AUTOSAR XML (schema 3.1.2)
package /Components/SWC_InThMdlT
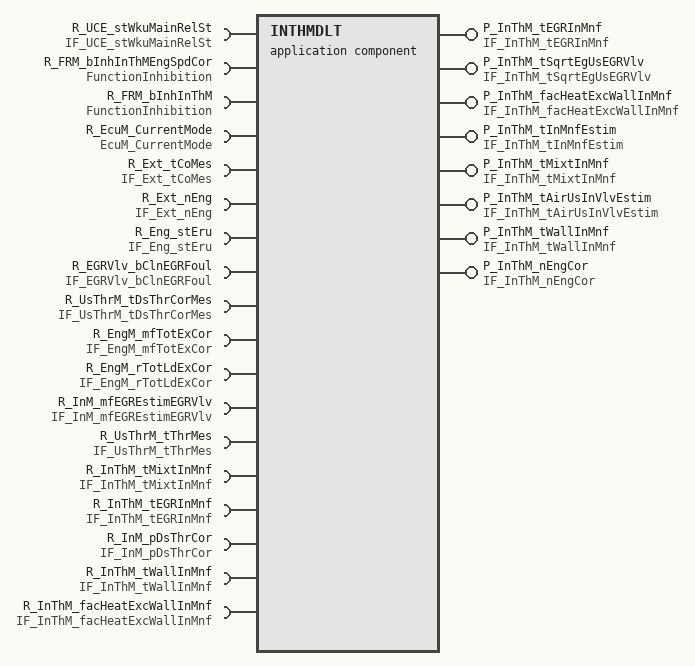
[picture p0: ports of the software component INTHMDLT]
  application software component type INTHMDLT  # InThMdlT
    require port R_UCE_stWkuMainRelSt: required-interface=IF_UCE_stWkuMainRelSt
    require port R_FRM_bInhInThMEngSpdCor: required-interface=FunctionInhibition
    require port R_FRM_bInhInThM: required-interface=FunctionInhibition
    8 x provide port:
      P_InThM_tEGRInMnf: unqueued-sender-com-spec{data-element=InThM_tEGRInMnf, can-invalidate=false, init-value=ConstantValue}, provided-interface=IF_InThM_tEGRInMnf
      P_InThM_tSqrtEgUsEGRVlv: unqueued-sender-com-spec{data-element=InThM_tSqrtEgUsEGRVlv, can-invalidate=false, init-value=ConstantValue1}, provided-interface=IF_InThM_tSqrtEgUsEGRVlv
      P_InThM_facHeatExcWallInMnf: unqueued-sender-com-spec{data-element=InThM_facHeatExcWallInMnf, can-invalidate=false, init-value=ConstantValue3}, provided-interface=IF_InThM_facHeatExcWallInMnf
      P_InThM_tInMnfEstim: unqueued-sender-com-spec{data-element=InThM_tInMnfEstim, can-invalidate=false, init-value=ConstantValue5}, provided-interface=IF_InThM_tInMnfEstim
      P_InThM_tMixtInMnf: unqueued-sender-com-spec{data-element=InThM_tMixtInMnf, can-invalidate=false, init-value=ConstantValue7}, provided-interface=IF_InThM_tMixtInMnf
      P_InThM_tAirUsInVlvEstim: unqueued-sender-com-spec{data-element=InThM_tAirUsInVlvEstim, can-invalidate=false, init-value=ConstantValue9}, provided-interface=IF_InThM_tAirUsInVlvEstim
      P_InThM_tWallInMnf: unqueued-sender-com-spec{data-element=InThM_tWallInMnf, can-invalidate=false, init-value=ConstantValue11}, provided-interface=IF_InThM_tWallInMnf
      P_InThM_nEngCor: unqueued-sender-com-spec{data-element=InThM_nEngCor, can-invalidate=false, init-value=ConstantValue13}, provided-interface=IF_InThM_nEngCor
    15 x require port:
      R_EcuM_CurrentMode: required-interface=EcuM_CurrentMode
      R_Ext_tCoMes: unqueued-receiver-com-spec{data-element=Ext_tCoMes, init-value=ConstantValue15, resync-time=0}, required-interface=IF_Ext_tCoMes
      R_Ext_nEng: unqueued-receiver-com-spec{data-element=Ext_nEng, init-value=ConstantValue17, resync-time=0}, required-interface=IF_Ext_nEng
      R_Eng_stEru: unqueued-receiver-com-spec{data-element=Eng_stEru, init-value=ConstantValue19, resync-time=0}, required-interface=IF_Eng_stEru
      R_EGRVlv_bClnEGRFoul: unqueued-receiver-com-spec{data-element=EGRVlv_bClnEGRFoul, init-value=ConstantValue21, resync-time=0}, required-interface=IF_EGRVlv_bClnEGRFoul
      R_UsThrM_tDsThrCorMes: unqueued-receiver-com-spec{data-element=UsThrM_tDsThrCorMes, init-value=UInt16InitValue, resync-time=0}, required-interface=IF_UsThrM_tDsThrCorMes
      R_EngM_mfTotExCor: unqueued-receiver-com-spec{data-element=EngM_mfTotExCor, init-value=ConstantValue23, resync-time=0}, required-interface=IF_EngM_mfTotExCor
      R_EngM_rTotLdExCor: unqueued-receiver-com-spec{data-element=EngM_rTotLdExCor, init-value=ConstantValue25, resync-time=0}, required-interface=IF_EngM_rTotLdExCor
      R_InM_mfEGREstimEGRVlv: unqueued-receiver-com-spec{data-element=InM_mfEGREstimEGRVlv, init-value=ConstantValue27, resync-time=0}, required-interface=IF_InM_mfEGREstimEGRVlv
      R_UsThrM_tThrMes: unqueued-receiver-com-spec{data-element=UsThrM_tThrMes, init-value=ConstantValue29, resync-time=0}, required-interface=IF_UsThrM_tThrMes
      R_InThM_tMixtInMnf: unqueued-receiver-com-spec{data-element=InThM_tMixtInMnf, init-value=ConstantValue31, resync-time=0}, required-interface=IF_InThM_tMixtInMnf
      R_InThM_tEGRInMnf: unqueued-receiver-com-spec{data-element=InThM_tEGRInMnf, init-value=ConstantValue, resync-time=0}, required-interface=IF_InThM_tEGRInMnf
      R_InM_pDsThrCor: unqueued-receiver-com-spec{data-element=InM_pDsThrCor, init-value=ConstantValue33, resync-time=0}, required-interface=IF_InM_pDsThrCor
      R_InThM_tWallInMnf: unqueued-receiver-com-spec{data-element=InThM_tWallInMnf, init-value=ConstantValue35, resync-time=0}, required-interface=IF_InThM_tWallInMnf
      R_InThM_facHeatExcWallInMnf: unqueued-receiver-com-spec{data-element=InThM_facHeatExcWallInMnf, init-value=ConstantValue37, resync-time=0}, required-interface=IF_InThM_facHeatExcWallInMnf
  23 x constant specification:
    ConstantValue
      value:
        integer literal ConstantValue: type=DT_InThM_tEGRInMnf, value=0
    ConstantValue1
      value:
        integer literal ConstantValue1: type=DT_InThM_tSqrtEgUsEGRVlv, value=0
    ConstantValue11
      value:
        integer literal ConstantValue11: type=DT_InThM_tWallInMnf, value=0
    ConstantValue13
      value:
        integer literal ConstantValue13: type=DT_InThM_nEngCor, value=0
    ConstantValue15
      value:
        integer literal ConstantValue15: type=DT_Ext_tCoMes, value=20
    ConstantValue17
      value:
        integer literal ConstantValue17: type=DT_Ext_nEng, value=0
    ConstantValue19
      value:
        integer literal ConstantValue19: type=DT_Eng_stEru, value=1
    ConstantValue21
      value:
        boolean literal ConstantValue21: type=DT_EGRVlv_bClnEGRFoul, value=false
    ConstantValue23
      value:
        integer literal ConstantValue23: type=DT_EngM_mfTotExCor, value=0
    ConstantValue25
      value:
        integer literal ConstantValue25: type=DT_EngM_rTotLdExCor, value=0
    ConstantValue27
      value:
        integer literal ConstantValue27: type=DT_InM_mfEGREstimEGRVlv, value=0
    ConstantValue29
      value:
        integer literal ConstantValue29: type=DT_UsThrM_tThrMes, value=0
    ConstantValue3
      value:
        integer literal ConstantValue3: type=DT_InThM_facHeatExcWallInMnf, value=0
    ConstantValue31
      value:
        integer literal ConstantValue31: type=DT_InThM_tMixtInMnf, value=0
    ConstantValue33
      value:
        integer literal ConstantValue33: type=DT_InM_pDsThrCor, value=0
    ConstantValue35
      value:
        integer literal ConstantValue35: type=DT_InThM_tWallInMnf, value=0
    ConstantValue37
      value:
        integer literal ConstantValue37: type=DT_InThM_facHeatExcWallInMnf, value=0
    ConstantValue5
      value:
        integer literal ConstantValue5: type=DT_InThM_tInMnfEstim, value=0
    ConstantValue7
      value:
        integer literal ConstantValue7: type=DT_InThM_tMixtInMnf, value=0
    ConstantValue9
      value:
        integer literal ConstantValue9: type=DT_InThM_tAirUsInVlvEstim, value=0
    InitValue_UInt16_0
      value:
        integer literal InitValue_UInt16_0: type=DT_InThM_tWallInCylHead_irv, value=0
    InitValue_UInt16_039
      value:
        integer literal InitValue_UInt16_039: type=DT_InThM_tEGRUsEGRVlv_irv, value=0
    UInt16InitValue
      value:
        integer literal UInt16InitValue: type=DT_UsThrM_tDsThrCorMes, value=0
  internal behavior IB_InThMdlT: component=INTHMDLT
    mode switch event EV_InThMdlT_001_MSE: start-on-event=RE_InThMdlT_001_MSE, activation=ENTRY, mode=R_EcuM_CurrentMode.currentMode.RUN
    6 x timing event, all with mode-dependency=dependent-on-mode=[R_UCE_stWkuMainRelSt.RCD_stWkuMainRelSt.PreMainWakeUp, R_UCE_stWkuMainRelSt.RCD_stWkuMainRelSt.PostMainWakeUp, R_UCE_stWkuMainRelSt.RCD_stWkuMainRelSt.Invalid]:
      EV_InThMdlT_006_TEV: start-on-event=RE_InThMdlT_006_TEV, period=4
      EV_InThMdlT_002_TEV: start-on-event=RE_InThMdlT_002_TEV, period=0.01
      EV_InThMdlT_008_TEV: start-on-event=RE_InThMdlT_008_TEV, period=0.01
      EV_InThMdlT_005_TEV: start-on-event=RE_InThMdlT_005_TEV, period=4
      EV_InThMdlT_007_TEV: start-on-event=RE_InThMdlT_007_TEV, period=0.01
      EV_InThMdlT_004_TEV: start-on-event=RE_InThMdlT_004_TEV, period=4
    inter runnable variable InThM_tEGRUsEGRVlv_irv: sw-calibration-access=READ-WRITE, type=DT_InThM_tEGRUsEGRVlv_irv, communication-approach=EXPLICIT, init-value=InitValue_UInt16_039
    inter runnable variable InThM_tWallInCylHead_irv: sw-calibration-access=READ-WRITE, type=DT_InThM_tWallInCylHead_irv, communication-approach=EXPLICIT, init-value=InitValue_UInt16_0
    7 x runnable:
      RE_InThMdlT_005_TEV: written-variable=InThM_tWallInCylHead_irv
        data receive point dr_Ext_tCoMes: data-element=R_Ext_tCoMes.Ext_tCoMes
      RE_InThMdlT_004_TEV
        data receive point dr_Eng_stEru: data-element=R_Eng_stEru.Eng_stEru
        data receive point dr_UsThrM_tThrMes: data-element=R_UsThrM_tThrMes.UsThrM_tThrMes
        data receive point dr_InThM_tEGRInMnf: data-element=R_InThM_tEGRInMnf.InThM_tEGRInMnf
      RE_InThMdlT_006_TEV
        5 x data receive point:
          dr_Eng_stEru: data-element=R_Eng_stEru.Eng_stEru
          dr_EngM_mfTotExCor: data-element=R_EngM_mfTotExCor.EngM_mfTotExCor
          dr_InThM_tMixtInMnf: data-element=R_InThM_tMixtInMnf.InThM_tMixtInMnf
          dr_InThM_tWallInMnf: data-element=R_InThM_tWallInMnf.InThM_tWallInMnf
          dr_UsThrM_tDsThrCorMes: data-element=R_UsThrM_tDsThrCorMes.UsThrM_tDsThrCorMes
      RE_InThMdlT_008_TEV: read-variable=InThM_tEGRUsEGRVlv_irv, written-variable=InThM_tEGRUsEGRVlv_irv
        data receive point dr_Ext_nEng: data-element=R_Ext_nEng.Ext_nEng
        data receive point dr_InM_mfEGREstimEGRVlv: data-element=R_InM_mfEGREstimEGRVlv.InM_mfEGREstimEGRVlv
        data receive point dr_EngM_rTotLdExCor: data-element=R_EngM_rTotLdExCor.EngM_rTotLdExCor
        data send point ds_InThM_tSqrtEgUsEGRVlv: data-element=P_InThM_tSqrtEgUsEGRVlv.InThM_tSqrtEgUsEGRVlv
      RE_InThMdlT_007_TEV: read-variable=InThM_tWallInCylHead_irv
        10 x data receive point:
          dr_Eng_stEru: data-element=R_Eng_stEru.Eng_stEru
          dr_EngM_mfTotExCor: data-element=R_EngM_mfTotExCor.EngM_mfTotExCor
          dr_InM_pDsThrCor: data-element=R_InM_pDsThrCor.InM_pDsThrCor
          dr_EGRVlv_bClnEGRFoul: data-element=R_EGRVlv_bClnEGRFoul.EGRVlv_bClnEGRFoul
          dr_Ext_nEng: data-element=R_Ext_nEng.Ext_nEng
          dr_InThM_tWallInMnf: data-element=R_InThM_tWallInMnf.InThM_tWallInMnf
          dr_InM_mfEGREstimEGRVlv: data-element=R_InM_mfEGREstimEGRVlv.InM_mfEGREstimEGRVlv
          DRP_R_InThM_facHeatExcWallInMnf_InThM_facHeatExcWallInMnf: data-element=R_InThM_facHeatExcWallInMnf.InThM_facHeatExcWallInMnf
          dr_InThM_tEGRInMnf: data-element=R_InThM_tEGRInMnf.InThM_tEGRInMnf
          dr_UsThrM_tThrMes: data-element=R_UsThrM_tThrMes.UsThrM_tThrMes
        5 x data send point:
          ds_InThM_facHeatExcWallInMnf: data-element=P_InThM_facHeatExcWallInMnf.InThM_facHeatExcWallInMnf
          ds_InThM_nEngCor: data-element=P_InThM_nEngCor.InThM_nEngCor
          ds_InThM_tInMnfEstim: data-element=P_InThM_tInMnfEstim.InThM_tInMnfEstim
          ds_InThM_tAirUsInVlvEstim: data-element=P_InThM_tAirUsInVlvEstim.InThM_tAirUsInVlvEstim
          ds_InThM_tMixtInMnf: data-element=P_InThM_tMixtInMnf.InThM_tMixtInMnf
        sync call ssp_FRM_bInhInThM: operation=R_FRM_bInhInThM.GetFunctionPermission
        sync call ssp_FRM_bInhInThMEngSpdCor: operation=R_FRM_bInhInThMEngSpdCor.GetFunctionPermission
      RE_InThMdlT_002_TEV: read-variable=[InThM_tEGRUsEGRVlv_irv, InThM_tWallInCylHead_irv]
        4 x data receive point:
          dr_UsThrM_tThrMes: data-element=R_UsThrM_tThrMes.UsThrM_tThrMes
          dr_InM_mfEGREstimEGRVlv: data-element=R_InM_mfEGREstimEGRVlv.InM_mfEGREstimEGRVlv
          dr_Eng_stEru: data-element=R_Eng_stEru.Eng_stEru
          dr_InThM_tEGRInMnf: data-element=R_InThM_tEGRInMnf.InThM_tEGRInMnf
      RE_InThMdlT_001_MSE: written-variable=[InThM_tWallInCylHead_irv, InThM_tEGRUsEGRVlv_irv]
        4 x data receive point:
          dr_Ext_tCoMes: data-element=R_Ext_tCoMes.Ext_tCoMes
          dr_UsThrM_tThrMes: data-element=R_UsThrM_tThrMes.UsThrM_tThrMes
          dr_UsThrM_tDsThrCorMes: data-element=R_UsThrM_tDsThrCorMes.UsThrM_tDsThrCorMes
          dr_Eng_stEru: data-element=R_Eng_stEru.Eng_stEru
        7 x data send point:
          ds_InThM_tEGRInMnf: data-element=P_InThM_tEGRInMnf.InThM_tEGRInMnf
          ds_InThM_tAirUsInVlvEstim: data-element=P_InThM_tAirUsInVlvEstim.InThM_tAirUsInVlvEstim
          ds_InThM_tWallInMnf: data-element=P_InThM_tWallInMnf.InThM_tWallInMnf
          ds_InThM_facHeatExcWallInMnf: data-element=P_InThM_facHeatExcWallInMnf.InThM_facHeatExcWallInMnf
          ds_InThM_tInMnfEstim: data-element=P_InThM_tInMnfEstim.InThM_tInMnfEstim
          ds_InThM_tSqrtEgUsEGRVlv: data-element=P_InThM_tSqrtEgUsEGRVlv.InThM_tSqrtEgUsEGRVlv
          ds_InThM_tMixtInMnf: data-element=P_InThM_tMixtInMnf.InThM_tMixtInMnf
  swc implementation Imp_InThMdlT: code-generator=Real-Time Workshop Embedded Coder 5.5 (R2010a) 25-Jan-2010, programming-language=C, behavior=IB_InThMdlT
    code-descriptors:
      code CodeDescriptor: type=SRC
        9 x xfile:
          InThMdlT_types_h: url=InThMdlT_types.h
          InThMdlT_import_h: url=InThMdlT_import.h
          InThMdlT_c: url=InThMdlT.c
          InThMdlT_Version_h: url=InThMdlT_Version.h
          InThMdlT_MemMap_h: url=InThMdlT_MemMap.h
          InThMdlT_h: url=InThMdlT.h
          InThMdlT_private_h: url=InThMdlT_private.h
          InThMdlT_Def_c: url=InThMdlT_Def.c
          InThMdlT_Version_c: url=InThMdlT_Version.c
package /Components/SWC_InThMdlT/InThMdlT_IRVDatatypes
  integer type DT_InThM_tEGRUsEGRVlv_irv: base-type=uint16, lower-limit=0, upper-limit=65535
  integer type DT_InThM_tWallInCylHead_irv: base-type=uint16, lower-limit=0, upper-limit=65535
